VERSION "HIPBNYYYYYYYYYYYYYYYYYYYYYYYYYYYYYYYYYYYYY/4/%%%/4/'%**4YYY///"

NS_ :

BS_:

BU_:

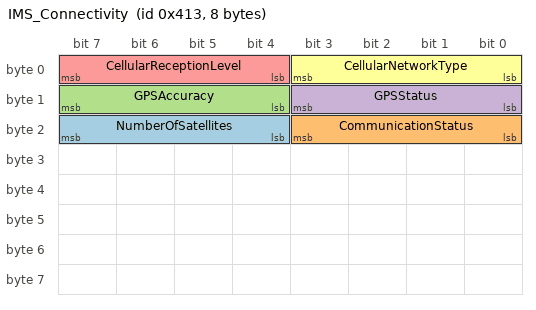
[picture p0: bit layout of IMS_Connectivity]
BO_ 1043 IMS_Connectivity: 8 Vector__XXX
 SG_ NumberOfSatellites : 20|4@1+ (1,0) [0|15] "" Vector__XXX
 SG_ CommunicationStatus : 16|4@1+ (1,0) [0|15] "" Vector__XXX
 SG_ GPSAccuracy : 12|4@1+ (1,0) [0|15] "" Vector__XXX
 SG_ GPSStatus : 8|4@1+ (1,0) [0|15] "" Vector__XXX
 SG_ CellularReceptionLevel : 4|4@1+ (1,0) [0|15] "" Vector__XXX
 SG_ CellularNetworkType : 0|4@1+ (1,0) [0|15] "" Vector__XXX

BA_DEF_  "BusType" STRING ;
BA_DEF_DEF_  "BusType" "CAN";
